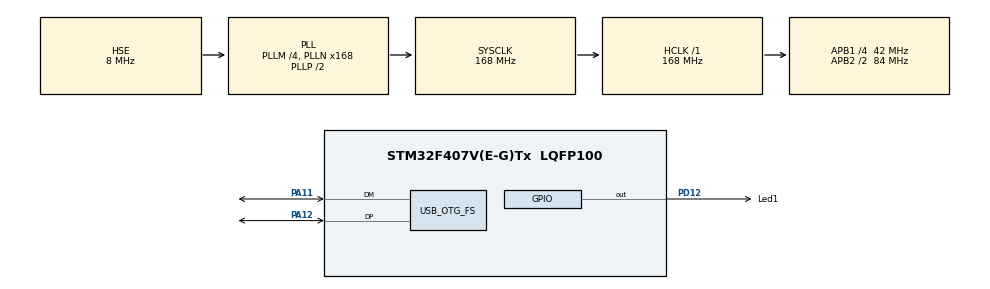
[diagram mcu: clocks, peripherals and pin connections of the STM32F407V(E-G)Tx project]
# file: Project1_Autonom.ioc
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FREERTOS.Tasks01=defaultTask,24,128,StartDefaultTask,Default,NULL,Dynamic,NULL,NULL;Task1,8,128,StartTask02,Default,NULL,Dynamic,NULL,NULL;Task2,8,128,StartTask03,Default,NULL,Dynamic,NULL,NULL
Mcu.Family=STM32F4
Mcu.Name=STM32F407V(E-G)Tx
Mcu.Package=LQFP100
NVIC.OTG_FS_IRQn=true\:5\:0\:false\:false\:true\:true\:false\:true
NVIC.PriorityGroup=NVIC_PRIORITYGROUP_4
NVIC.TIM6_DAC_IRQn=true\:0\:0\:false\:false\:true\:false\:false\:true
NVIC.TimeBase=TIM6_DAC_IRQn
NVIC.TimeBaseIP=TIM6
PA11.Mode=Device_Only
PA11.Signal=USB_OTG_FS_DM
PA12.Mode=Device_Only
PA12.Signal=USB_OTG_FS_DP
PA13.Mode=Serial_Wire
PA13.Signal=SYS_JTMS-SWDIO
PA14.Mode=Serial_Wire
PA14.Signal=SYS_JTCK-SWCLK
PD12.GPIO_Label=Led1
PD12.Signal=GPIO_Output
PH0-OSC_IN.Mode=HSE-External-Oscillator
PH0-OSC_IN.Signal=RCC_OSC_IN
PH1-OSC_OUT.Mode=HSE-External-Oscillator
PH1-OSC_OUT.Signal=RCC_OSC_OUT
ProjectManager.HeapSize=0x200
ProjectManager.StackSize=0x400
ProjectManager.TargetToolchain=MDK-ARM V5.27
RCC.48MHZClocksFreq_Value=48000000
RCC.AHBFreq_Value=168000000
RCC.APB1CLKDivider=RCC_HCLK_DIV4
RCC.APB1Freq_Value=42000000
RCC.APB1TimFreq_Value=84000000
RCC.APB2CLKDivider=RCC_HCLK_DIV2
RCC.APB2Freq_Value=84000000
RCC.APB2TimFreq_Value=168000000
RCC.CortexFreq_Value=168000000
RCC.HCLKFreq_Value=168000000
RCC.HSE_VALUE=8000000
RCC.HSI_VALUE=16000000
RCC.LSE_VALUE=32768
RCC.PLLM=4
RCC.PLLN=168
RCC.PLLQ=7
RCC.SYSCLKFreq_VALUE=168000000
RCC.SYSCLKSource=RCC_SYSCLKSOURCE_PLLCLK
RCC.VCOOutputFreq_Value=336000000
USB_DEVICE.CLASS_NAME_FS=CDC
USB_DEVICE.VirtualMode-CDC_FS=Cdc
USB_DEVICE.VirtualModeFS=Cdc_FS
USB_OTG_FS.VirtualMode=Device_Only
VP_FREERTOS_VS_CMSIS_V2.Mode=CMSIS_V2
VP_SYS_VS_tim6.Mode=TIM6
VP_USB_DEVICE_VS_USB_DEVICE_CDC_FS.Mode=CDC_FS
board=custom

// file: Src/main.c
/* USER CODE BEGIN Header */
/**
  ******************************************************************************
  * @file           : main.c
  * @brief          : Main program body
  ******************************************************************************
  * @attention
  *
  * <h2><center>&copy; Copyright (c) 2022 STMicroelectronics.
  * All rights reserved.</center></h2>
  *
  * This software component is licensed by ST under Ultimate Liberty license
  * SLA0044, the "License"; You may not use this file except in compliance with
  * the License. You may obtain a copy of the License at:
  *                             www.st.com/SLA0044
  *
  ******************************************************************************
  */
/* USER CODE END Header */

#include "main.h"
#include "cmsis_os.h"
#include "usb_device.h"

/* USER CODE BEGIN Includes */
#include "string.h"
#include <stdio.h>
#include <stdlib.h>
#include <ctype.h>
#include "App.h"
/* USER CODE END Includes */

/* USER CODE BEGIN PTD */
extern uint8_t UserRxBufferFS[];
extern uint8_t CDC_Transmit_FS(uint8_t* Buf, uint16_t Len);
uint16_t TaskFlag = 0,ledOnTime,ledOffTime;

/* USER CODE END PTD */

/* Definitions for defaultTask */
osThreadId_t defaultTaskHandle;
const osThreadAttr_t defaultTask_attributes = {
  .name = "defaultTask",
  .priority = (osPriority_t) osPriorityNormal,
  .stack_size = 128
};
/* Definitions for Task1 */
osThreadId_t Task1Handle;
const osThreadAttr_t Task1_attributes = {
  .name = "Task1",
  .priority = (osPriority_t) osPriorityLow,
  .stack_size = 128
};
/* Definitions for Task2 */
osThreadId_t Task2Handle;
const osThreadAttr_t Task2_attributes = {
  .name = "Task2",
  .priority = (osPriority_t) osPriorityLow,
  .stack_size = 128
};

void SystemClock_Config(void);
static void MX_GPIO_Init(void);
void StartDefaultTask(void *argument);
void StartTask02(void *argument);
void StartTask03(void *argument);

int main(void)
{

  /* MCU Configuration--------------------------------------------------------*/

  /* Reset of all peripherals, Initializes the Flash interface and the Systick. */
  HAL_Init();

  /* Configure the system clock */
  SystemClock_Config();

  /* Initialize all configured peripherals */
  MX_GPIO_Init();
  /* USER CODE BEGIN 2 */
   Send_UID();
	//printf("unique = %s\n",uniqueBuf);
  /* USER CODE END 2 */
  /* Init scheduler */
  osKernelInitialize();

  /* Create the thread(s) */
  /* creation of defaultTask */
  defaultTaskHandle = osThreadNew(StartDefaultTask, NULL, &defaultTask_attributes);

  /* creation of Task1 */
  Task1Handle = osThreadNew(StartTask02, NULL, &Task1_attributes);

  /* creation of Task2 */
  Task2Handle = osThreadNew(StartTask03, NULL, &Task2_attributes);

  /* Start scheduler */
  osKernelStart();

  /* We should never get here as control is now taken by the scheduler */

  /* Infinite loop */
  while (1)
  {

  }
}

void SystemClock_Config(void)
{
  RCC_OscInitTypeDef RCC_OscInitStruct = {0};
  RCC_ClkInitTypeDef RCC_ClkInitStruct = {0};

  /** Configure the main internal regulator output voltage
  */
  __HAL_RCC_PWR_CLK_ENABLE();
  __HAL_PWR_VOLTAGESCALING_CONFIG(PWR_REGULATOR_VOLTAGE_SCALE1);
  /** Initializes the CPU, AHB and APB busses clocks
  */
  RCC_OscInitStruct.OscillatorType = RCC_OSCILLATORTYPE_HSE;
  RCC_OscInitStruct.HSEState = RCC_HSE_ON;
  RCC_OscInitStruct.PLL.PLLState = RCC_PLL_ON;
  RCC_OscInitStruct.PLL.PLLSource = RCC_PLLSOURCE_HSE;
  RCC_OscInitStruct.PLL.PLLM = 4;
  RCC_OscInitStruct.PLL.PLLN = 168;
  RCC_OscInitStruct.PLL.PLLP = RCC_PLLP_DIV2;
  RCC_OscInitStruct.PLL.PLLQ = 7;
  if (HAL_RCC_OscConfig(&RCC_OscInitStruct) != HAL_OK)
  {
    Error_Handler();
  }
  /** Initializes the CPU, AHB and APB busses clocks
  */
  RCC_ClkInitStruct.ClockType = RCC_CLOCKTYPE_HCLK|RCC_CLOCKTYPE_SYSCLK
                              |RCC_CLOCKTYPE_PCLK1|RCC_CLOCKTYPE_PCLK2;
  RCC_ClkInitStruct.SYSCLKSource = RCC_SYSCLKSOURCE_PLLCLK;
  RCC_ClkInitStruct.AHBCLKDivider = RCC_SYSCLK_DIV1;
  RCC_ClkInitStruct.APB1CLKDivider = RCC_HCLK_DIV4;
  RCC_ClkInitStruct.APB2CLKDivider = RCC_HCLK_DIV2;

  if (HAL_RCC_ClockConfig(&RCC_ClkInitStruct, FLASH_LATENCY_5) != HAL_OK)
  {
    Error_Handler();
  }
}

static void MX_GPIO_Init(void)
{
  GPIO_InitTypeDef GPIO_InitStruct = {0};

  /* GPIO Ports Clock Enable */
  __HAL_RCC_GPIOH_CLK_ENABLE();
  __HAL_RCC_GPIOD_CLK_ENABLE();
  __HAL_RCC_GPIOA_CLK_ENABLE();

  /*Configure GPIO pin Output Level */
  HAL_GPIO_WritePin(Led1_GPIO_Port, Led1_Pin, GPIO_PIN_RESET);

  /*Configure GPIO pin : Led1_Pin */
  GPIO_InitStruct.Pin = Led1_Pin;
  GPIO_InitStruct.Mode = GPIO_MODE_OUTPUT_PP;
  GPIO_InitStruct.Pull = GPIO_NOPULL;
  GPIO_InitStruct.Speed = GPIO_SPEED_FREQ_LOW;
  HAL_GPIO_Init(Led1_GPIO_Port, &GPIO_InitStruct);

}

void StartDefaultTask(void *argument)
{
  /* init code for USB_DEVICE */
  MX_USB_DEVICE_Init();
  /* USER CODE BEGIN 5 */
  /* Infinite loop */
  for(;;)
  {
    osDelay(1000);
  }
  /* USER CODE END 5 */
}

void StartTask02(void *argument)
{
  /* USER CODE BEGIN StartTask02 */
  /* Infinite loop */

  for(;;)
  {

		if(!TaskFlag)
		{

		ToLower();
		if(strstr((char *)UserRxBufferFS,"ledon=") != NULL)
		{
			ledOnTime = atoi((char *)&UserRxBufferFS[6]);
//			printf("LED Time ON = %d\n", ledOnTime);
			memset(UserRxBufferFS, 0, 64);
		}
		else if(strstr((char *)UserRxBufferFS,"ledoff=") != NULL)
		{
			ledOffTime = atoi((char *)&UserRxBufferFS[7]);
		//	printf("LED Time OFF = %d\n", ledOffTime);
			memset(UserRxBufferFS, 0, 64);
		}

			HAL_GPIO_WritePin(GPIOD,GPIO_PIN_12,GPIO_PIN_SET);
			osDelay(ledOnTime);
			HAL_GPIO_WritePin(GPIOD,GPIO_PIN_12,GPIO_PIN_RESET);
			osDelay(ledOffTime);
		}
  }
  /* USER CODE END StartTask02 */
}

void StartTask03(void *argument)
{
  /* USER CODE BEGIN StartTask03 */
  /* Infinite loop */
for(;;)
  {

		ToLower();
		if(strstr((char *)UserRxBufferFS,"stop") != NULL)
		{
			TaskFlag = 1;
			HAL_GPIO_WritePin(GPIOD,GPIO_PIN_12,GPIO_PIN_SET);
			osDelay(1000);
			HAL_GPIO_WritePin(GPIOD,GPIO_PIN_12,GPIO_PIN_RESET);
			osDelay(1000);

		}
		else if(strstr((char *)UserRxBufferFS,"start") != NULL)
		{
		  TaskFlag = 0;
			memset(UserRxBufferFS, 0, 64);
		}

  }
  /* USER CODE END StartTask03 */
}

void HAL_TIM_PeriodElapsedCallback(TIM_HandleTypeDef *htim)
{
  if (htim->Instance == TIM6) {
    HAL_IncTick();
  }
}

void Error_Handler(void)
{
}

/************************ (C) COPYRIGHT STMicroelectronics *****END OF FILE****/
